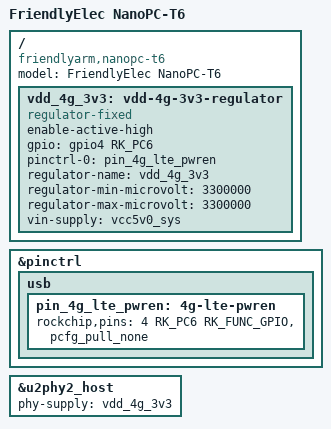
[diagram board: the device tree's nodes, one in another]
// SPDX-License-Identifier: (GPL-2.0+ OR MIT)
/*
 * Copyright (c) 2021 Rockchip Electronics Co., Ltd.
 * Copyright (c) 2023 Thomas McKahan
 * Copyright (c) 2024 Linaro Ltd.
 *
 */

/dts-v1/;

#include "rk3588-nanopc-t6.dtsi"

/ {
	model = "FriendlyElec NanoPC-T6";
	compatible = "friendlyarm,nanopc-t6", "rockchip,rk3588";

	vdd_4g_3v3: vdd-4g-3v3-regulator {
		compatible = "regulator-fixed";
		enable-active-high;
		gpio = <&gpio4 RK_PC6 GPIO_ACTIVE_HIGH>;
		pinctrl-names = "default";
		pinctrl-0 = <&pin_4g_lte_pwren>;
		regulator-name = "vdd_4g_3v3";
		regulator-min-microvolt = <3300000>;
		regulator-max-microvolt = <3300000>;
		vin-supply = <&vcc5v0_sys>;
	};
};

&pinctrl {
	usb {
		pin_4g_lte_pwren: 4g-lte-pwren {
			rockchip,pins = <4 RK_PC6 RK_FUNC_GPIO &pcfg_pull_none>;
		};
	};
};

&u2phy2_host {
	phy-supply = <&vdd_4g_3v3>;
};
